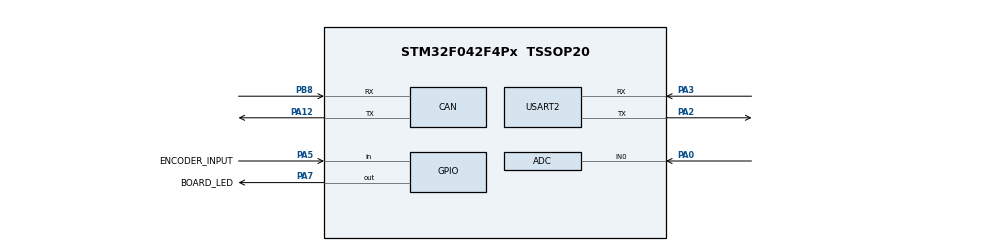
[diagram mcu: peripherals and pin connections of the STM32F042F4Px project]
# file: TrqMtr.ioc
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CAN.CalculateTimeQuantum=2000.0
Mcu.Family=STM32F0
Mcu.Name=STM32F042F4Px
Mcu.Package=TSSOP20
PA0.Mode=IN0
PA0.Signal=ADC_IN0
PA12.Mode=Master
PA12.Signal=CAN_TX
PA13.Mode=Serial_Wire
PA13.Signal=SYS_SWDIO
PA14.Mode=Serial_Wire
PA14.Signal=SYS_SWCLK
PA2.Mode=Asynchronous
PA2.Signal=USART2_TX
PA3.Mode=Asynchronous
PA3.Signal=USART2_RX
PA5.GPIO_Label=ENCODER_INPUT
PA5.Signal=GPIO_Input
PA7.GPIO_Label=BOARD_LED
PA7.Signal=GPIO_Output
PB8.Mode=Master
PB8.Signal=CAN_RX
ProjectManager.HeapSize=0x200
ProjectManager.StackSize=0x400
ProjectManager.TargetToolchain=Makefile
USART2.VirtualMode-Asynchronous=VM_ASYNC
VP_SYS_VS_PINREMAP.Mode=PINREMAP
board=custom

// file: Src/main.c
/* USER CODE BEGIN Header */
/**
  ******************************************************************************
  * @file           : main.c
  * @brief          : Main program body
  ******************************************************************************
  * @attention
  *
  * <h2><center>&copy; Copyright (c) 2019 STMicroelectronics.
  * All rights reserved.</center></h2>
  *
  * This software component is licensed by ST under BSD 3-Clause license,
  * the "License"; You may not use this file except in compliance with the
  * License. You may obtain a copy of the License at:
  *                        opensource.org/licenses/BSD-3-Clause
  *
  ******************************************************************************
  */
/* USER CODE END Header */

#include "main.h"

ADC_HandleTypeDef hadc;

CAN_HandleTypeDef hcan;

UART_HandleTypeDef huart2;

void SystemClock_Config(void);
static void MX_GPIO_Init(void);
static void MX_ADC_Init(void);
static void MX_CAN_Init(void);
static void MX_USART2_UART_Init(void);

int main(void)
{

  /* MCU Configuration--------------------------------------------------------*/

  /* Reset of all peripherals, Initializes the Flash interface and the Systick. */
  HAL_Init();

  /* Configure the system clock */
  SystemClock_Config();

  /* Initialize all configured peripherals */
  MX_GPIO_Init();
  MX_ADC_Init();
  MX_CAN_Init();
  MX_USART2_UART_Init();

  /* Infinite loop */
  while (1)
  {

    /* USER CODE BEGIN 3 */

    //Heartbeat led / Blink test program
    HAL_GPIO_TogglePin(BOARD_LED_GPIO_Port, BOARD_LED_Pin);
    HAL_Delay(3000);
  }
  /* USER CODE END 3 */
}

void SystemClock_Config(void)
{
  RCC_OscInitTypeDef RCC_OscInitStruct = {0};
  RCC_ClkInitTypeDef RCC_ClkInitStruct = {0};

  /** Initializes the CPU, AHB and APB busses clocks
  */
  RCC_OscInitStruct.OscillatorType = RCC_OSCILLATORTYPE_HSI|RCC_OSCILLATORTYPE_HSI14;
  RCC_OscInitStruct.HSIState = RCC_HSI_ON;
  RCC_OscInitStruct.HSI14State = RCC_HSI14_ON;
  RCC_OscInitStruct.HSICalibrationValue = RCC_HSICALIBRATION_DEFAULT;
  RCC_OscInitStruct.HSI14CalibrationValue = 16;
  RCC_OscInitStruct.PLL.PLLState = RCC_PLL_NONE;
  if (HAL_RCC_OscConfig(&RCC_OscInitStruct) != HAL_OK)
  {
    Error_Handler();
  }
  /** Initializes the CPU, AHB and APB busses clocks
  */
  RCC_ClkInitStruct.ClockType = RCC_CLOCKTYPE_HCLK|RCC_CLOCKTYPE_SYSCLK
                              |RCC_CLOCKTYPE_PCLK1;
  RCC_ClkInitStruct.SYSCLKSource = RCC_SYSCLKSOURCE_HSI;
  RCC_ClkInitStruct.AHBCLKDivider = RCC_SYSCLK_DIV1;
  RCC_ClkInitStruct.APB1CLKDivider = RCC_HCLK_DIV1;

  if (HAL_RCC_ClockConfig(&RCC_ClkInitStruct, FLASH_LATENCY_0) != HAL_OK)
  {
    Error_Handler();
  }
}

static void MX_ADC_Init(void)
{

  ADC_ChannelConfTypeDef sConfig = {0};

  /** Configure the global features of the ADC (Clock, Resolution, Data Alignment and number of conversion)
  */
  hadc.Instance = ADC1;
  hadc.Init.ClockPrescaler = ADC_CLOCK_ASYNC_DIV1;
  hadc.Init.Resolution = ADC_RESOLUTION_12B;
  hadc.Init.DataAlign = ADC_DATAALIGN_RIGHT;
  hadc.Init.ScanConvMode = ADC_SCAN_DIRECTION_FORWARD;
  hadc.Init.EOCSelection = ADC_EOC_SINGLE_CONV;
  hadc.Init.LowPowerAutoWait = DISABLE;
  hadc.Init.LowPowerAutoPowerOff = DISABLE;
  hadc.Init.ContinuousConvMode = DISABLE;
  hadc.Init.DiscontinuousConvMode = DISABLE;
  hadc.Init.ExternalTrigConv = ADC_SOFTWARE_START;
  hadc.Init.ExternalTrigConvEdge = ADC_EXTERNALTRIGCONVEDGE_NONE;
  hadc.Init.DMAContinuousRequests = DISABLE;
  hadc.Init.Overrun = ADC_OVR_DATA_PRESERVED;
  if (HAL_ADC_Init(&hadc) != HAL_OK)
  {
    Error_Handler();
  }
  /** Configure for the selected ADC regular channel to be converted.
  */
  sConfig.Channel = ADC_CHANNEL_0;
  sConfig.Rank = ADC_RANK_CHANNEL_NUMBER;
  sConfig.SamplingTime = ADC_SAMPLETIME_1CYCLE_5;
  if (HAL_ADC_ConfigChannel(&hadc, &sConfig) != HAL_OK)
  {
    Error_Handler();
  }

}

static void MX_CAN_Init(void)
{

  hcan.Instance = CAN;
  hcan.Init.Prescaler = 16;
  hcan.Init.Mode = CAN_MODE_NORMAL;
  hcan.Init.SyncJumpWidth = CAN_SJW_1TQ;
  hcan.Init.TimeSeg1 = CAN_BS1_1TQ;
  hcan.Init.TimeSeg2 = CAN_BS2_1TQ;
  hcan.Init.TimeTriggeredMode = DISABLE;
  hcan.Init.AutoBusOff = DISABLE;
  hcan.Init.AutoWakeUp = DISABLE;
  hcan.Init.AutoRetransmission = DISABLE;
  hcan.Init.ReceiveFifoLocked = DISABLE;
  hcan.Init.TransmitFifoPriority = DISABLE;
  if (HAL_CAN_Init(&hcan) != HAL_OK)
  {
    Error_Handler();
  }

}

static void MX_USART2_UART_Init(void)
{

  huart2.Instance = USART2;
  huart2.Init.BaudRate = 38400;
  huart2.Init.WordLength = UART_WORDLENGTH_8B;
  huart2.Init.StopBits = UART_STOPBITS_1;
  huart2.Init.Parity = UART_PARITY_NONE;
  huart2.Init.Mode = UART_MODE_TX_RX;
  huart2.Init.HwFlowCtl = UART_HWCONTROL_NONE;
  huart2.Init.OverSampling = UART_OVERSAMPLING_16;
  huart2.Init.OneBitSampling = UART_ONE_BIT_SAMPLE_DISABLE;
  huart2.AdvancedInit.AdvFeatureInit = UART_ADVFEATURE_NO_INIT;
  if (HAL_UART_Init(&huart2) != HAL_OK)
  {
    Error_Handler();
  }

}

static void MX_GPIO_Init(void)
{
  GPIO_InitTypeDef GPIO_InitStruct = {0};

  /* GPIO Ports Clock Enable */
  __HAL_RCC_GPIOB_CLK_ENABLE();
  __HAL_RCC_GPIOA_CLK_ENABLE();

  /*Configure GPIO pin Output Level */
  HAL_GPIO_WritePin(BOARD_LED_GPIO_Port, BOARD_LED_Pin, GPIO_PIN_RESET);

  /*Configure GPIO pin : ENCODER_INPUT_Pin */
  GPIO_InitStruct.Pin = ENCODER_INPUT_Pin;
  GPIO_InitStruct.Mode = GPIO_MODE_INPUT;
  GPIO_InitStruct.Pull = GPIO_NOPULL;
  HAL_GPIO_Init(ENCODER_INPUT_GPIO_Port, &GPIO_InitStruct);

  /*Configure GPIO pin : BOARD_LED_Pin */
  GPIO_InitStruct.Pin = BOARD_LED_Pin;
  GPIO_InitStruct.Mode = GPIO_MODE_OUTPUT_PP;
  GPIO_InitStruct.Pull = GPIO_NOPULL;
  GPIO_InitStruct.Speed = GPIO_SPEED_FREQ_LOW;
  HAL_GPIO_Init(BOARD_LED_GPIO_Port, &GPIO_InitStruct);

}

void Error_Handler(void)
{
}

/************************ (C) COPYRIGHT STMicroelectronics *****END OF FILE****/
